# tviibe1m register map
Vendor: Infineon Technologies; Series: TVIIBE1M; File version: 1.0
CPU: CM4 r0p1, little endian, MPU, FPU, VTOR, 3 interrupt priority bits
Registers are 32-bit, read-write, reset 0x0 unless marked. A register's access mark holds for its fields unless they carry their own. Offsets are from the block's base; [hi:lo] are bit positions; lines under a group give offsets from that group; {n}, {i} and the like mark numbered series; 'fields as' and 'values as' point back to an identical list.

## IPC
Base 0x40220000
{0x0+0x20*i} STRUCT[{i}] (i=0..7) group — IPC structure
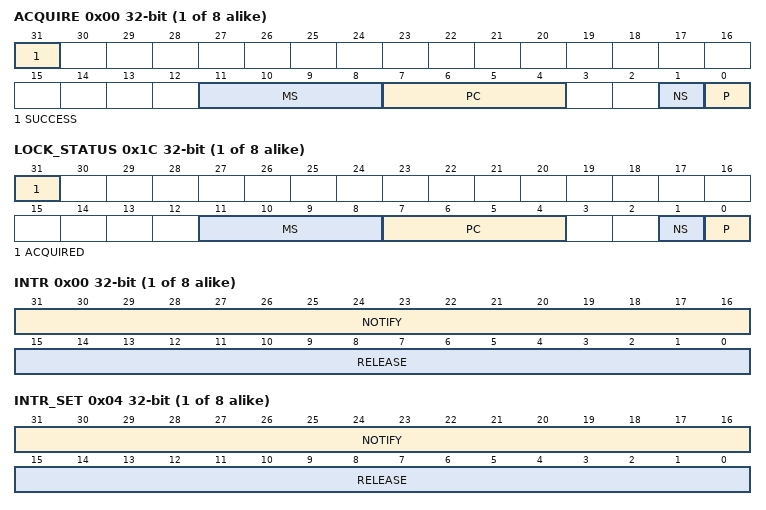
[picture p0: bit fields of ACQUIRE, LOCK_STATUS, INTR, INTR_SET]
  0x00 ACQUIRE ro (reset mask 0x80000000) — IPC acquire
    [31] SUCCESS — Specifies if the lock is successfully acquired or not (reading the ACQUIRE register can have affect on SUCCESS and LOCK_STATUS.ACQUIRED): '0': Not successfully acquired; i.e. the lock was already acquired by another read transaction and not released. The P, NS, PC and MS fields reflect the access attributes of the transaction that previously successfully acuired the lock; the fields are NOT affected by the current access. '1': Successfully acquired. The P, NS, PC and MS fields reflect the access attributes of the current access. Note that this field is NOT SW writable. A lock is released by writing to the associated RELEASE register (irrespective of the write value).
    [11:8] MS — This field specifies the bus master identifier that successfully acquired the lock.
    [7:4] PC — This field specifies the protection context that successfully acquired the lock.
    [1] NS — Secure/non-secure access control: '0': secure. '1': non-secure. This field is set with the secure/non-secure access control of the access that successfully acquired the lock.
    [0] P — User/privileged access control: '0': user mode. '1': privileged mode. This field is set with the user/privileged access control of the access that successfully acquired the lock.
  0x04 RELEASE wo — IPC release
    [15:0] INTR_RELEASE — Writing this field releases a lock and allows for the generation of release events to the IPC interrupt structures, but only when the lock is acquired (LOCK_STATUS.ACQUIRED is '1'). The IPC release cause fields associated with this IPC structure are set to '1', but only for those IPC interrupt structures for which the corresponding bit field in INTR_RELEASE[] is set to '1'. SW writes a '1' to the bit fields to generate a release event. Due to the transient nature of this event, SW always reads a '0' from this field.
  0x08 NOTIFY wo — IPC notification
    [15:0] INTR_NOTIFY — This field allows for the generation of notification events to the IPC interrupt structures. The IPC notification cause fields associated with this IPC structure are set to '1', but only for those IPC interrupt structures for which the corresponding bit field in INTR_NOTIFY[] is set to '1'. SW writes a '1' to the bit fields to generate a notify event. Due to the transient nature of this event, SW always reads a '0' from this field.
  0x0C DATA0 reset not defined — IPC data 0
    [31:0] DATA — This field holds a 32-bit data element that is associated with the IPC structure.
  0x10 DATA1 reset not defined — IPC data 1
    fields as STRUCT[0].DATA0
  0x1C LOCK_STATUS ro (reset mask 0x80000000) — IPC lock status
    [31] ACQUIRED — Specifies if the lock is acquired. This field is set to '1', if a ACQUIRE read transfer successfully acquires the lock (the ACQUIRE read transfer returns ACQUIRE.SUCCESS as '1'). If zero, P, NS, PC, and MS are not valid.
    [11:8] MS — This field specifies the bus master identifier that successfully acquired the lock.
    [7:4] PC — This field specifies the protection context that successfully acquired the lock.
    [1] NS — This field specifies the secure/non-secure access control: '0': secure. '1': non-secure.
    [0] P — This field specifies the user/privileged access control: '0': user mode. '1': privileged mode.
{0x1000+0x20*i} INTR_STRUCT[{i}] (i=0..7) group — IPC interrupt structure
  0x00 INTR — Interrupt
    [31:16] NOTIFY — These interrupt cause fields are activated (HW sets the field to '1') when a IPC notification event is detected. One bit field for each master. SW writes a '1' to these field to clear the interrupt cause.
    [15:0] RELEASE — These interrupt cause fields are activated (HW sets the field to '1') when a IPC release event is detected. One bit field for each master. SW writes a '1' to these field to clear the interrupt cause.
  0x04 INTR_SET — Interrupt set
    [31:16] NOTIFY — SW writes a '1' to this field to set the corresponding field in the INTR register.
    [15:0] RELEASE — SW writes a '1' to this field to set the corresponding field in the INTR register.
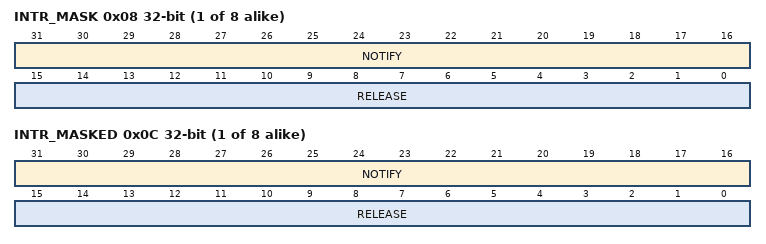
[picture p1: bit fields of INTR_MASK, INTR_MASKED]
  0x08 INTR_MASK — Interrupt mask
    [31:16] NOTIFY — Mask bit for corresponding field in the INTR register.
    [15:0] RELEASE — Mask bit for corresponding field in the INTR register.
  0x0C INTR_MASKED ro — Interrupt masked
    [31:16] NOTIFY — Logical and of corresponding INTR and INTR_MASK fields.
    [15:0] RELEASE — Logical and of corresponding request and mask bits.

## CANFD0 (part 1 of 3) — CAN Controller
Base 0x40520000
Same registers: CANFD1 0x40540000
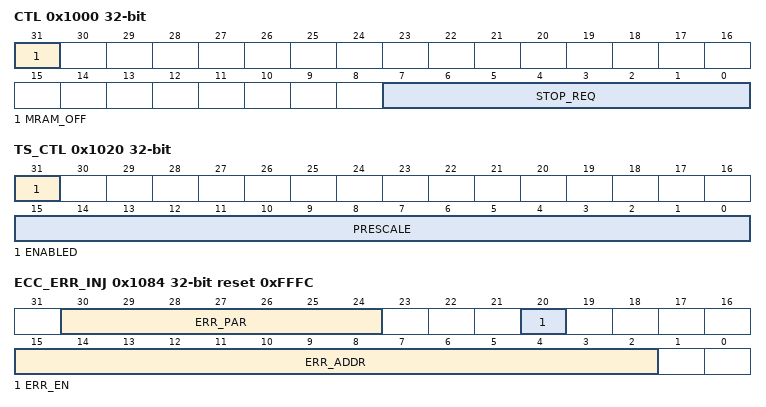
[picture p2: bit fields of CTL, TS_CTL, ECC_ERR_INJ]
0x1000 CTL — Global CAN control register
  [31] MRAM_OFF — MRAM off 0= Default MRAM on (with MRAM retained in DeepSleep). 1= Switch MRAM off (not retained) to save power. Before setting this bit all the CAN channels have to be powered down using the STOP_REQ/ACK bits. When the MRAM is off any access attempt to it is considered an address error (as if MRAM_SIZE=0). After switching the MRAM on again software needs to allow for a certain power up time before MRAM can be used, i.e. before STOP_REQ can be de-asserted. The power up time is equivalent to the system SRAM power up time specified in the CPUSS.RAM_PWR_DELAY_CTL register. MRAM_OFF should be set to 0 prior to transitioning to Hibernate mode.
  [7:0] STOP_REQ
0x1004 STATUS ro — Global CAN status register
  [7:0] STOP_ACK — Clock Stop Acknowledge for each TTCAN IP. These bits are directly driven by m_ttcan_clkstop_ack of each TTCAN IP. When this bit is set the corresponding TTCAN IP clocks will be gated off, except HCLK will enabled for each AHB write
0x1010 INTR0_CAUSE ro — Consolidated interrupt0 cause register
  [7:0] INT0 — Show pending m_ttcan_int0 of each channel
0x1014 INTR1_CAUSE ro — Consolidated interrupt1 cause register
  [7:0] INT1 — Show pending m_ttcan_int1 of each channel
0x1020 TS_CTL — Time Stamp control register
  [31] ENABLED — Counter enable bit 0 = Count disabled. Stop counting up and keep the counter value 1 = Count enabled. Start counting up from the current value
  [15:0] PRESCALE — Time Stamp counter prescale value. When enabled divide the Host clock (HCLK) by PRESCALE+1 to create Time Stamp clock ticks.
0x1024 TS_CNT — Time Stamp counter value
  [15:0] VALUE — The counter value of the Time Stamp Counter. When enabled this counter will count Time Stamp clock ticks from the pre-scaler. When written this counter and the pre-scaler will reset to 0 (write data is ignored).
0x1080 ECC_CTL — ECC control
  [16] ECC_EN — Enable ECC for CANFD SRAM When disabled also all error injection functionality is disabled.
0x1084 ECC_ERR_INJ reset 0xFFFC — ECC error injection
  [30:24] ERR_PAR — ECC Parity bits to use for ECC error injection at address ERR_ADDR.
  [20] ERR_EN — Enable error injection (ECC_EN must be 1). When this bit is set the error parity (ERR_PAR) will be used when an AHB write is done to the ERR_ADDR address. When the error word is read a single or double error will be reported to the fault structure just like for a real ECC error (even if this bit is no longer set). When this bit is set (and ECC_EN=1) a non-correctable error (ECC or address error) for the ERR_ADDR will not be reported back to the CAN channel or AHB bus.
  [15:2] ERR_ADDR — Specifies the address of the word where an error will be injected on write or an non-correctable error will be suppressed. When the ERR_EN bit is set an error parity (ERR_PAR) is injected when any write, from bus or a CAN channel, is done to this address. When the ERR_EN bit is set and the access address matches ERR_ADDR then a non-correctable ECC error or an Address error will NOT result in a bus error or CAN channel shutdown. Note that error reporting to the fault structure cannot be suppressed.

## Notices in the file
(c) (2016-2026), Infineon Technologies AG
or an affiliate of Infineon Technologies AG.
SPDX-License-Identifier: Apache-2.0
Licensed under the Apache License, Version 2.0 (the "License");
you may not use this file except in compliance with the License.
You may obtain a copy of the License at
http://www.apache.org/licenses/LICENSE-2.0
Unless required by applicable law or agreed to in writing, software
distributed under the License is distributed on an "AS IS" BASIS,
WITHOUT WARRANTIES OR CONDITIONS OF ANY KIND, either express or implied.
See the License for the specific language governing permissions and
limitations under the License.
